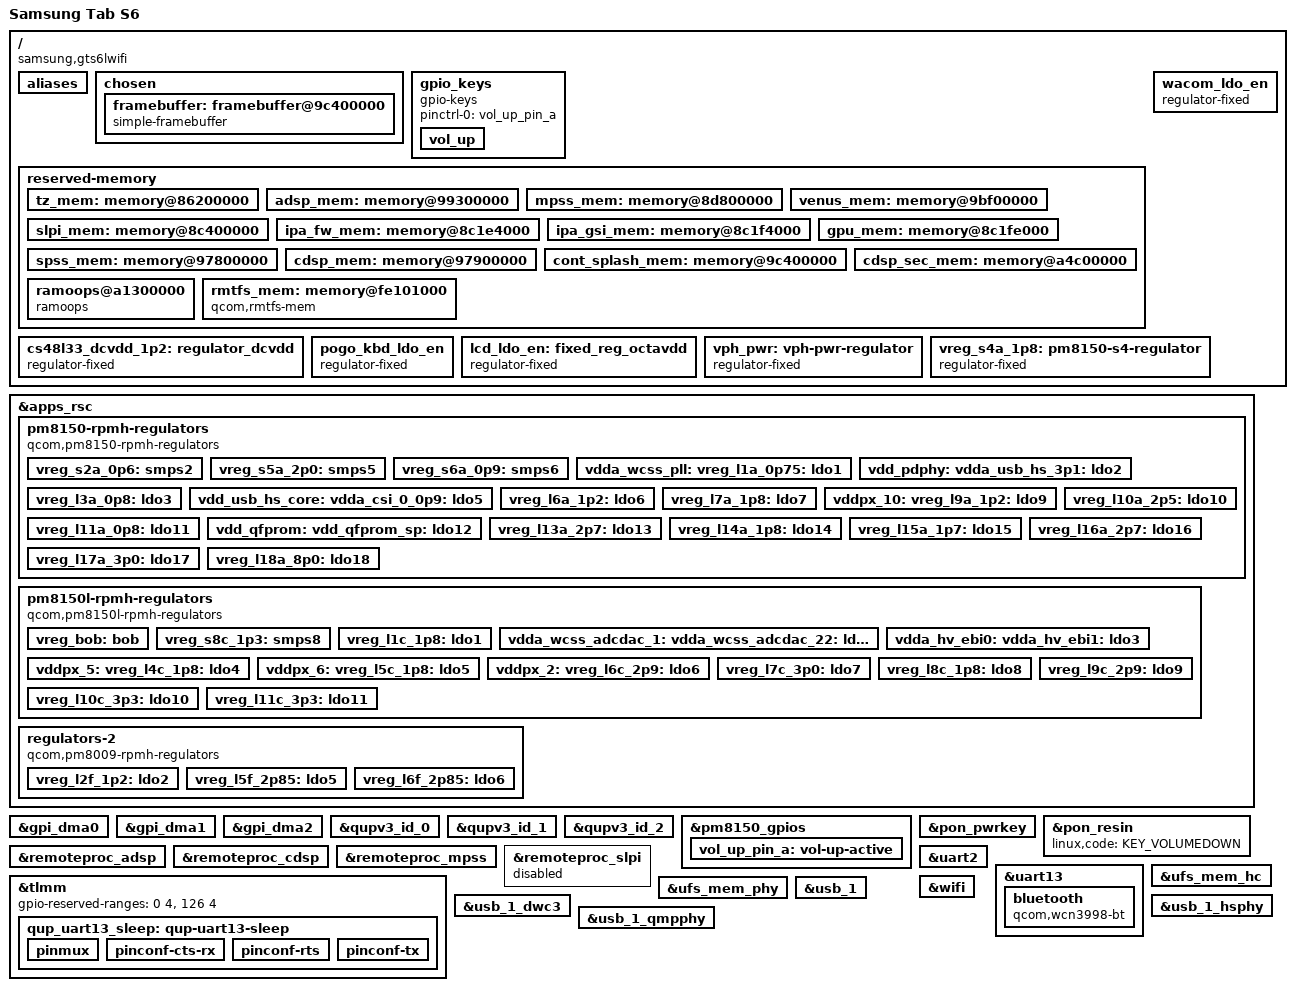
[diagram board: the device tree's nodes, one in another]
// SPDX-License-Identifier: BSD-3-Clause
/*
 * Copyright (c) 2026, Zeyan Li <qaz6750@outlook.com>
 */

/dts-v1/;

#include <dt-bindings/gpio/gpio.h>
#include <dt-bindings/input/input.h>
#include <dt-bindings/input/gpio-keys.h>
#include <dt-bindings/pinctrl/qcom,pmic-gpio.h>
#include <dt-bindings/regulator/qcom,rpmh-regulator.h>
#include "sm8150.dtsi"
#include "pm8009.dtsi"
#include "pm8150.dtsi"
#include "pm8150l.dtsi"

/delete-node/ &tz_mem;
/delete-node/ &rmtfs_mem;
/delete-node/ &adsp_mem;
/delete-node/ &mpss_mem;
/delete-node/ &venus_mem;
/delete-node/ &slpi_mem;
/delete-node/ &ipa_fw_mem;
/delete-node/ &ipa_gsi_mem;
/delete-node/ &gpu_mem;
/delete-node/ &spss_mem;
/delete-node/ &cdsp_mem;

/ {
	model = "Samsung Tab S6";
	compatible = "samsung,gts6lwifi", "qcom,sm8150-mtp", "qcom,sm8150";
	qcom,msm-id = <339 0x20000>;
    qcom,board-id = <0x00010008 0x00000002>;

	aliases {
		serial0 = &uart2;
		display0 = &framebuffer;
		hsuart0 = &uart13;
		wifi0 = &wifi;
	};

	chosen {
		#address-cells = <2>;
		#size-cells = <2>;
		ranges;

		framebuffer: framebuffer@9c400000 {
			compatible = "simple-framebuffer";
			reg = <0 0x9c400000 0 0x2000000>;
			status = "okay";
			width = <2560>;
			height = <1600>;
			stride = <(2560 * 4)>;
			format = "a8r8g8b8";
			clocks =	<&gcc GCC_DISP_HF_AXI_CLK>,
						<&gcc GCC_DISP_SF_AXI_CLK>;
		};
	};

	gpio_keys {
		compatible = "gpio-keys";
		pinctrl-names = "default";
		pinctrl-0 = <&vol_up_pin_a>;

		vol_up {
			label = "volume_up";
			gpios = <&pm8150l_gpios 12 GPIO_ACTIVE_LOW>;
			linux,input-type = <1>;
			linux,code = <KEY_VOLUMEUP>;
			debounce-interval = <15>;
			linux,can-disable;
		};
	};

	reserved-memory {
		tz_mem: memory@86200000 {
			no-map;
			reg = <0x0 0x86200000 0x0 0x5fe4000>;
		};

		adsp_mem: memory@99300000 {
			no-map;
			reg = <0x0 0x99300000 0x0 0x2700000>;
		};

		mpss_mem: memory@8d800000 {
			no-map;
			reg = <0x0 0x8d800000 0x0 0xa000000>;
		};

		venus_mem: memory@9bf00000 {
			no-map;
			reg = <0x0 0x9bf00000 0x0 0x500000>;
		};

		slpi_mem: memory@8c400000 {
			no-map;
			reg = <0x0 0x8c400000 0x0 0x1400000>;
		};

		ipa_fw_mem: memory@8c1e4000 {
			no-map;
			reg = <0x0 0x8c1e4000 0x0 0x10000>;
		};

		ipa_gsi_mem: memory@8c1f4000 {
			no-map;
			reg = <0x0 0x8c1f4000 0x0 0x5000>;
		};

		gpu_mem: memory@8c1fe000 {
			no-map;
			reg = <0x0 0x8c1fe000 0x0 0x2000>;
		};

		spss_mem: memory@97800000 {
			no-map;
			reg = <0x0 0x97800000 0x0 0x100000>;
		};

		cdsp_mem: memory@97900000 {
			no-map;
			reg = <0x0 0x97900000 0x0 0x1a00000>;
		};

		cont_splash_mem: memory@9c400000 {
			reg = <0x0 0x9c400000 0x0 0x2000000>;
            label = "cont_splash_region";
		};

		cdsp_sec_mem: memory@a4c00000 {
			reg = <0x0 0xa4c00000 0x0 0x1400000>;
			no-map;
		};

		ramoops@a1300000 {
			compatible = "ramoops";
			reg = <0x0 0xc1300000 0x0 0x800000>;
			console-size = <0x400000>;
			ecc-size = <0>;
			ftrace-size = <0>;
			pmsg-size = <0x200000>;
			record-size = <0>;
			no-map;
		};

		rmtfs_mem: memory@fe101000 {
			compatible = "qcom,rmtfs-mem";
			reg = <0 0xfe101000 0 0x300000>;
			no-map;

			qcom,client-id = <1>;
			qcom,vmid = <15>;
		};
	};

	cs48l33_dcvdd_1p2: regulator_dcvdd {
		compatible = "regulator-fixed";
		regulator-name = "regulator-dcvdd-supply";
		status = "ok";
		regulator-min-microvolt = <1200000>;
		regulator-max-microvolt = <1200000>;
		gpio = <&tlmm 60 0>; /* VOICE_LDO_ENABLE */
		enable-active-high;
		startup-delay-us = <10000>;
	};

	wacom_ldo_en: wacom_ldo_en {
		compatible = "regulator-fixed";
		regulator-name = "wacom_3.3v";
		regulator-min-microvolt = <3300000>;
		regulator-max-microvolt = <3300000>;
		gpio = <&tlmm 68 0>;
		enable-active-high;
		regulator-boot-on;
	};

	pogo_kbd_ldo_en: pogo_kbd_ldo_en {
		compatible = "regulator-fixed";
		regulator-name = "pogo_kbd_ldo_en_3.3v";
		regulator-min-microvolt = <3300000>;
		regulator-max-microvolt = <3300000>;
		gpio = <&tlmm 65 0>;
		enable-active-high;
	};

	lcd_ldo_en: fixed_reg_octavdd {
		compatible = "regulator-fixed";
		status = "okay";
		regulator-name = "octa-vdd";
		gpio = <&tlmm 113 0>; /* LCD_LDO_EN */
		enable-active-high;
		regulator-boot-on;
	};

	vph_pwr: vph-pwr-regulator {
		compatible = "regulator-fixed";
		regulator-name = "vph_pwr";
		regulator-min-microvolt = <3700000>;
		regulator-max-microvolt = <3700000>;
	};

	/* S4 is modeled as a fixed regulator in vendor sources */
	vreg_s4a_1p8: pm8150-s4-regulator {
		compatible = "regulator-fixed";
		regulator-name = "vreg_s4a_1p8";

		regulator-min-microvolt = <1800000>;
		regulator-max-microvolt = <1800000>;

		regulator-always-on;
		regulator-boot-on;

		vin-supply = <&vph_pwr>;
	};
};

&apps_rsc {
	pm8150-rpmh-regulators {
		compatible = "qcom,pm8150-rpmh-regulators";
		qcom,pmic-id = "a";

		vdd-s1-supply = <&vph_pwr>;
		vdd-s2-supply = <&vph_pwr>;
		vdd-s3-supply = <&vph_pwr>;
		vdd-s4-supply = <&vph_pwr>;
		vdd-s5-supply = <&vph_pwr>;
		vdd-s6-supply = <&vph_pwr>;
		vdd-s7-supply = <&vph_pwr>;
		vdd-s8-supply = <&vph_pwr>;
		vdd-s9-supply = <&vph_pwr>;
		vdd-s10-supply = <&vph_pwr>;

		vdd-l1-l8-l11-supply = <&vreg_s6a_0p9>;
		vdd-l2-l10-supply = <&vreg_bob>;
		vdd-l3-l4-l5-l18-supply = <&vreg_s6a_0p9>;
		vdd-l6-l9-supply = <&vreg_s8c_1p3>;
		vdd-l7-l12-l14-l15-supply = <&vreg_s5a_2p0>;
		vdd-l13-l16-l17-supply = <&vreg_bob>;

		vreg_s2a_0p6: smps2 {
			regulator-min-microvolt = <600000>;
			regulator-max-microvolt = <600000>;
		};

		vreg_s5a_2p0: smps5 {
			regulator-min-microvolt = <2000000>;
			regulator-max-microvolt = <2000000>;
		};

		vreg_s6a_0p9: smps6 {
			regulator-min-microvolt = <920000>;
			regulator-max-microvolt = <1128000>;
		};

		vdda_wcss_pll:
		vreg_l1a_0p75: ldo1 {
			regulator-min-microvolt = <752000>;
			regulator-max-microvolt = <752000>;
			regulator-initial-mode = <RPMH_REGULATOR_MODE_HPM>;
		};

		vdd_pdphy:
		vdda_usb_hs_3p1:
		vreg_l2a_3p1: ldo2 {
			regulator-min-microvolt = <3072000>;
			regulator-max-microvolt = <3072000>;
			regulator-initial-mode = <RPMH_REGULATOR_MODE_HPM>;
		};

		vreg_l3a_0p8: ldo3 {
			regulator-min-microvolt = <480000>;
			regulator-max-microvolt = <932000>;
			regulator-initial-mode = <RPMH_REGULATOR_MODE_HPM>;
		};

		vdd_usb_hs_core:
		vdda_csi_0_0p9:
		vdda_csi_1_0p9:
		vdda_csi_2_0p9:
		vdda_csi_3_0p9:
		vdda_dsi_0_0p9:
		vdda_dsi_1_0p9:
		vdda_dsi_0_pll_0p9:
		vdda_dsi_1_pll_0p9:
		vdda_pcie_1ln_core:
		vdda_pcie_2ln_core:
		vdda_pll_hv_cc_ebi01:
		vdda_pll_hv_cc_ebi23:
		vdda_qrefs_0p875_5:
		vdda_sp_sensor:
		vdda_ufs_2ln_core_1:
		vdda_ufs_2ln_core_2:
		vdda_usb_ss_dp_core_1:
		vdda_usb_ss_dp_core_2:
		vdda_qlink_lv:
		vdda_qlink_lv_ck:
		vreg_l5a_0p875: ldo5 {
			regulator-min-microvolt = <880000>;
			regulator-max-microvolt = <880000>;
			regulator-initial-mode = <RPMH_REGULATOR_MODE_HPM>;
		};

		vreg_l6a_1p2: ldo6 {
			regulator-min-microvolt = <1200000>;
			regulator-max-microvolt = <1200000>;
			regulator-initial-mode = <RPMH_REGULATOR_MODE_HPM>;
		};

		vreg_l7a_1p8: ldo7 {
			regulator-min-microvolt = <1800000>;
			regulator-max-microvolt = <1800000>;
			regulator-initial-mode = <RPMH_REGULATOR_MODE_HPM>;
		};

		vddpx_10:
		vreg_l9a_1p2: ldo9 {
			regulator-min-microvolt = <1200000>;
			regulator-max-microvolt = <1200000>;
			regulator-initial-mode = <RPMH_REGULATOR_MODE_HPM>;
		};

		vreg_l10a_2p5: ldo10 {
			regulator-min-microvolt = <2504000>;
			regulator-max-microvolt = <2960000>;
			regulator-initial-mode = <RPMH_REGULATOR_MODE_HPM>;
		};

		vreg_l11a_0p8: ldo11 {
			regulator-min-microvolt = <800000>;
			regulator-max-microvolt = <800000>;
			regulator-initial-mode = <RPMH_REGULATOR_MODE_HPM>;
		};

		vdd_qfprom:
		vdd_qfprom_sp:
		vdda_apc_cs_1p8:
		vdda_gfx_cs_1p8:
		vdda_usb_hs_1p8:
		vdda_qrefs_vref_1p8:
		vddpx_10_a:
		vreg_l12a_1p8: ldo12 {
			regulator-min-microvolt = <1800000>;
			regulator-max-microvolt = <1800000>;
			regulator-initial-mode = <RPMH_REGULATOR_MODE_HPM>;
		};

		vreg_l13a_2p7: ldo13 {
			regulator-min-microvolt = <2800000>;
			regulator-max-microvolt = <2900000>;
			regulator-initial-mode = <RPMH_REGULATOR_MODE_HPM>;
		};

		vreg_l14a_1p8: ldo14 {
			regulator-min-microvolt = <1880000>;
			regulator-max-microvolt = <1880000>;
			regulator-initial-mode = <RPMH_REGULATOR_MODE_HPM>;
			regulator-boot-on;
		};

		vreg_l15a_1p7: ldo15 {
			regulator-min-microvolt = <1704000>;
			regulator-max-microvolt = <1704000>;
			regulator-initial-mode = <RPMH_REGULATOR_MODE_HPM>;
		};

		vreg_l16a_2p7: ldo16 {
			regulator-min-microvolt = <2704000>;
			regulator-max-microvolt = <2960000>;
			regulator-initial-mode = <RPMH_REGULATOR_MODE_HPM>;
		};

		vreg_l17a_3p0: ldo17 {
			regulator-min-microvolt = <3300000>;
			regulator-max-microvolt = <3300000>;
			regulator-initial-mode = <RPMH_REGULATOR_MODE_HPM>;
			regulator-boot-on;
		};

		vreg_l18a_8p0: ldo18 {
			regulator-min-microvolt = <880000>;
			regulator-max-microvolt = <880000>;
			regulator-initial-mode = <RPMH_REGULATOR_MODE_HPM>;
		};
	};

	pm8150l-rpmh-regulators {
		compatible = "qcom,pm8150l-rpmh-regulators";
		qcom,pmic-id = "c";

		vdd-s1-supply = <&vph_pwr>;
		vdd-s2-supply = <&vph_pwr>;
		vdd-s3-supply = <&vph_pwr>;
		vdd-s4-supply = <&vph_pwr>;
		vdd-s5-supply = <&vph_pwr>;
		vdd-s6-supply = <&vph_pwr>;
		vdd-s7-supply = <&vph_pwr>;
		vdd-s8-supply = <&vph_pwr>;

		vdd-l1-l8-supply = <&vreg_s4a_1p8>;
		vdd-l2-l3-supply = <&vreg_s8c_1p3>;
		vdd-l4-l5-l6-supply = <&vreg_bob>;
		vdd-l7-l11-supply = <&vreg_bob>;
		vdd-l9-l10-supply = <&vreg_bob>;

		vdd-bob-supply = <&vph_pwr>;
		vdd-flash-supply = <&vreg_bob>;
		vdd-rgb-supply = <&vreg_bob>;

		vreg_bob: bob {
			regulator-min-microvolt = <3008000>;
			regulator-max-microvolt = <4000000>;
			regulator-initial-mode = <RPMH_REGULATOR_MODE_AUTO>;
			regulator-allow-bypass;
		};

		vreg_s8c_1p3: smps8 {
			regulator-min-microvolt = <1352000>;
			regulator-max-microvolt = <1352000>;
		};

		vreg_l1c_1p8: ldo1 {
			regulator-min-microvolt = <1800000>;
			regulator-max-microvolt = <1800000>;
			regulator-initial-mode = <RPMH_REGULATOR_MODE_HPM>;
		};

		vdda_wcss_adcdac_1:
		vdda_wcss_adcdac_22:
		vreg_l2c_1p3: ldo2 {
			regulator-min-microvolt = <1304000>;
			regulator-max-microvolt = <1304000>;
			regulator-initial-mode = <RPMH_REGULATOR_MODE_HPM>;
		};

		vdda_hv_ebi0:
		vdda_hv_ebi1:
		vdda_hv_ebi2:
		vdda_hv_ebi3:
		vdda_hv_refgen0:
		vdda_mipi_dsi0_1p2:
		vdda_mipi_dsi1_1p2:
		vdda_qlink_hv_ck:
		vreg_l3c_1p2: ldo3 {
			regulator-min-microvolt = <1200000>;
			regulator-max-microvolt = <1200000>;
			regulator-initial-mode = <RPMH_REGULATOR_MODE_HPM>;
		};

		vddpx_5:
		vreg_l4c_1p8: ldo4 {
			regulator-min-microvolt = <1704000>;
			regulator-max-microvolt = <2928000>;
			regulator-initial-mode = <RPMH_REGULATOR_MODE_HPM>;
		};

		vddpx_6:
		vreg_l5c_1p8: ldo5 {
			regulator-min-microvolt = <1704000>;
			regulator-max-microvolt = <2928000>;
			regulator-initial-mode = <RPMH_REGULATOR_MODE_HPM>;
		};

		vddpx_2:
		vreg_l6c_2p9: ldo6 {
			regulator-min-microvolt = <1800000>;
			regulator-max-microvolt = <2960000>;
			regulator-initial-mode = <RPMH_REGULATOR_MODE_HPM>;
		};

		vreg_l7c_3p0: ldo7 {
			regulator-min-microvolt = <3000000>;
			regulator-max-microvolt = <3312000>;
			regulator-initial-mode = <RPMH_REGULATOR_MODE_HPM>;
		};

		vreg_l8c_1p8: ldo8 {
			regulator-min-microvolt = <1800000>;
			regulator-max-microvolt = <1800000>;
			regulator-initial-mode = <RPMH_REGULATOR_MODE_HPM>;
		};

		vreg_l9c_2p9: ldo9 {
			regulator-min-microvolt = <2704000>;
			regulator-max-microvolt = <2960000>;
			regulator-initial-mode = <RPMH_REGULATOR_MODE_HPM>;
		};

		vreg_l10c_3p3: ldo10 {
			regulator-min-microvolt = <3000000>;
			regulator-max-microvolt = <3312000>;
			regulator-initial-mode = <RPMH_REGULATOR_MODE_HPM>;
		};

		vreg_l11c_3p3: ldo11 {
			regulator-min-microvolt = <3000000>;
			regulator-max-microvolt = <3312000>;
			regulator-initial-mode = <RPMH_REGULATOR_MODE_HPM>;
		};
	};

	regulators-2 {
		compatible = "qcom,pm8009-rpmh-regulators";
		qcom,pmic-id = "f";

		vdd-s1-supply = <&vph_pwr>;
		vdd-s2-supply = <&vreg_bob>;

		vdd-l2-supply = <&vreg_s8c_1p3>;
		vdd-l5-l6-supply = <&vreg_bob>;

		vreg_l2f_1p2: ldo2 {
			regulator-min-microvolt = <1200000>;
			regulator-max-microvolt = <1200000>;
			regulator-initial-mode = <RPMH_REGULATOR_MODE_HPM>;
		};

		vreg_l5f_2p85: ldo5 {
			regulator-min-microvolt = <2800000>;
			regulator-max-microvolt = <2800000>;
			regulator-initial-mode = <RPMH_REGULATOR_MODE_HPM>;
		};

		vreg_l6f_2p85: ldo6 {
			regulator-initial-mode = <RPMH_REGULATOR_MODE_HPM>;
			regulator-min-microvolt = <2856000>;
			regulator-max-microvolt = <2856000>;
		};
	};
};

&gpi_dma0 {
	status = "okay";
};

&gpi_dma1 {
	status = "okay";
};

&gpi_dma2 {
	status = "okay";
};

&qupv3_id_0 {
	status = "okay";
};

&qupv3_id_1 {
	status = "okay";
};

&qupv3_id_2 {
	status = "okay";
};

&pm8150_gpios {
	vol_up_pin_a: vol-up-active {
		pins = "gpio12";
		function = "normal";
		input-enable;
		bias-pull-up;
		qcom,drive-strength = <PMIC_GPIO_STRENGTH_NO>;
	};
};

&pon_pwrkey {
	status = "okay";
};

&pon_resin {
	linux,code = <KEY_VOLUMEDOWN>;
	status = "okay";
};

&remoteproc_adsp {
	status = "okay";
	firmware-name = "qcom/sm8150/samsung/gts6lwifi/adsp.mbn";
};

&remoteproc_cdsp {
	status = "okay";
	firmware-name = "qcom/sm8150/samsung/gts6lwifi/cdsp.mbn";
};

&remoteproc_mpss {
	status = "okay";
	firmware-name = "qcom/sm8150/samsung/gts6lwifi/modem.mbn";
};

&remoteproc_slpi {
	status = "disabled";
	firmware-name = "qcom/sm8150/samsung/gts6lwifi/slpi.mbn";
};

&tlmm {
	/* gpios 0..3 are NFC spi, gpios 126..129 are FP spi */
	gpio-reserved-ranges = <0 4>, <126 4>;

	qup_uart13_sleep: qup-uart13-sleep {
		pinmux {
			pins = "gpio43", "gpio44", "gpio46";
			function = "qup13";
		};

		pinconf-cts-rx {
			pins = "gpio43", "gpio46";
			drive-strength = <2>;
			bias-disable;
		};

		pinconf-rts {
			pins = "gpio44";
			drive-strength = <2>;
			bias-pull-down;
		};

		pinconf-tx {
			pins = "gpio45";
			drive-strength = <2>;
			bias-pull-up;
		};
	};
};

&uart2 {
	status = "okay";
};

&uart13 {
	status = "okay";

	/delete-property/interrupts;
	interrupts-extended = <&intc GIC_SPI 585 IRQ_TYPE_LEVEL_HIGH>,
				<&tlmm 46 IRQ_TYPE_EDGE_FALLING>;

	pinctrl-names = "default", "sleep";
	pinctrl-1 = <&qup_uart13_sleep>;

	bluetooth: bluetooth {
		compatible = "qcom,wcn3998-bt";
		vddio-supply = <&vreg_l1a_0p75>;
		vddxo-supply = <&vreg_l7a_1p8>;
		vddrf-supply = <&vreg_l2c_1p3>;
		vddch0-supply = <&vreg_l11c_3p3>;
		max-speed = <3200000>;
		firmware-name = "gts6lwifi/crnv21.bin";
	};
};

&ufs_mem_hc {
	status = "okay";
};

&ufs_mem_phy {
	status = "okay";
};

&usb_1 {
	status = "okay";
};

&usb_1_dwc3 {
	snps,has-lpm-erratum;
	snps,hird-threshold = /bits/ 8 <0x10>;
	maximum-speed = "high-speed";
	dr_mode = "host";
};

&usb_1_hsphy {
	status = "okay";
	vdda-pll-supply = <&vreg_l5a_0p875>;
	vdda18-supply = <&vreg_l12a_1p8>;
	vdda33-supply = <&vreg_l2a_3p1>;
};

&usb_1_qmpphy {
	status = "okay";
	vdda-phy-supply = <&vreg_l3c_1p2>;
	vdda-pll-supply = <&vreg_l5a_0p875>;
};

&wifi {
	status = "okay";

	vdd-0.8-cx-mx-supply = <&vdda_wcss_pll>;
	vdd-1.8-xo-supply = <&vreg_l7a_1p8>;
	vdd-1.3-rfa-supply = <&vreg_l2c_1p3>;
	vdd-3.3-ch0-supply = <&vreg_l11c_3p3>;
};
